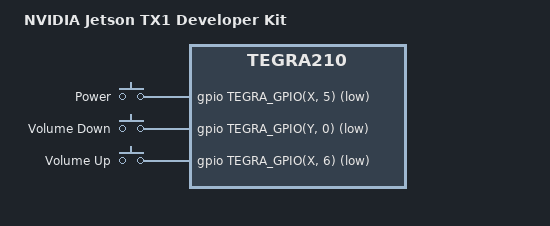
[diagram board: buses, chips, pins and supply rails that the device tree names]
/dts-v1/;

#include "tegra210-p2180.dtsi"
#include "tegra210-p2597.dtsi"
#include <dt-bindings/input/input.h>

/ {
	model = "NVIDIA Jetson TX1 Developer Kit";
	compatible = "nvidia,p2371-2180", "nvidia,tegra210";

	gpio-keys {
		compatible = "gpio-keys";
		label = "gpio-keys";

		power {
			label = "Power";
			gpios = <&gpio TEGRA_GPIO(X, 5) GPIO_ACTIVE_LOW>;
			linux,code = <KEY_POWER>;
			gpio-key,wakeup;
		};

		volume_down {
			label = "Volume Down";
			gpios = <&gpio TEGRA_GPIO(Y, 0) GPIO_ACTIVE_LOW>;
			linux,code = <KEY_VOLUMEDOWN>;
		};

		volume_up {
			label = "Volume Up";
			gpios = <&gpio TEGRA_GPIO(X, 6) GPIO_ACTIVE_LOW>;
			linux,code = <KEY_VOLUMEUP>;
		};
	};
};
